# R7FA6M3AH register map
Vendor: Renesas; Series: RA6; File version: 1.2
CPU: CM4 r0p1, little endian, MPU, FPU, VTOR, 4 interrupt priority bits
Registers are 32-bit, read-write, reset 0x0 unless marked. A register's access mark holds for its fields unless they carry their own. Offsets are from the block's base; [hi:lo] are bit positions; {n}, {i} and the like mark numbered series; 'fields as' and 'values as' point back to an identical list.

## EPTPC_CFG — EPTPC Configulation
Base 0x40064500
0x00 PTRSTR — EPTPC Reset Register
  [0] RESET — EPTPC Software Reset
    0=Do not reset the EPTPC; 1=Reset the EPTPC. Do not access the EPTPC-related registers other than this register while a software reset is being issued.
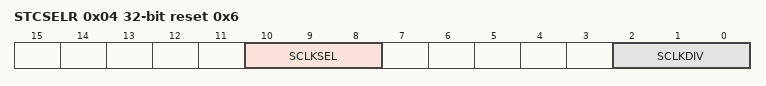
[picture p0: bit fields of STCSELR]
0x04 STCSELR reset 0x6 — STCA Clock Select Register
  [10:8] SCLKSEL — STCA Clock Select
    0=PCLKA clock divided by 1 to 6; 2=Input clock from the REF50CK0 pin; other=others (Settings other than above are prohibited.)
  [2:0] SCLKDIV — PCLKA Clock Frequency Division
    1=1; {v}=1/{v} (v=2..6); other=others (Settings other than above are prohibited.)
0x08 BYPASS — Bypass 1588 module Register
  [0] BYPASS0 — Bypass 1588 module for Ether 0ch
    0=to use 1588 module for Ether 0ch; 1=to bypass 1588 module for Ether 0ch

## CRC — CRC Calculator
Base 0x40074000
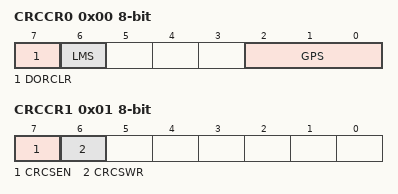
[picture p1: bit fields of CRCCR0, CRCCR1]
0x00 CRCCR0 8-bit — CRC Control Register0
  [7] DORCLR wo — CRCDOR Register Clear
    0=No effect; 1=Clears the CRCDOR register
  [6] LMS — CRC Calculation Switching
    0=Generates CRC for LSB first communication; 1=Generates CRC for MSB first communication
  [2:0] GPS — CRC Generating Polynomial Switching
    0=No calculation is executed; 1=8-bit CRC-8 (X8 + X2 + X + 1); 2=16-bit CRC-16 (X16 + X15 + X2 + 1); 3=16-bit CRC-CCITT (X16 + X12 + X5 + 1); 4=32-bit CRC-32 (X32+X26+X23+X22+X16+X12+X11+X10+X8+X7+X5+X4+X2+X+1); 5=32-bit CRC-32C (X32+X28+X27+X26+ X25+X23+X22+X20+X19+X18+X14+X13+X11+X10+X9+X8+X6+1); other=others (No calculation is executed.)
0x01 CRCCR1 8-bit — CRC Control Register1
  [7] CRCSEN — Snoop enable bit
    0=Disabled; 1=Enabled
  [6] CRCSWR — Snoop-on-write/read switch bit
    0=Snoop-on-read; 1=Snoop-on-write
0x04 CRCDIR — CRC Data Input Register
  [31:0] CRCDIR — Calculation input Data (Case of CRC-32, CRC-32C )
0x04 CRCDIR_BY 8-bit (alternate view of CRCDIR) — CRC Data Input Register (byte access)
  [7:0] CRCDIR_BY — Calculation input Data ( Case of CRC-8, CRC-16 or CRC-CCITT )
0x08 CRCDOR — CRC Data Output Register
  [31:0] CRCDOR — Calculation output Data (Case of CRC-32, CRC-32C )
0x08 CRCDOR_HA 16-bit (alternate view of CRCDOR) — CRC Data Output Register (halfword access)
  [15:0] CRCDOR_HA — Calculation output Data (Case of CRC-16 or CRC-CCITT )
0x08 CRCDOR_BY 8-bit (alternate view of CRCDOR) — CRC Data Output Register(byte access)
  [7:0] CRCDOR_BY — Calculation output Data (Case of CRC-8 )
0x0C CRCSAR 16-bit — Snoop Address Register
  [13:0] CRCSA — snoop address bitSet the I/O register address to snoop
    3=SCI0.TDR; 5=SCI0.RDR; 35=SCI1.TDR; 37=SCI1.RDR; 67=SCI2.TDR; 69=SCI2.RDR; 99=SCI3.TDR; 101=SCI3.RDR; 131=SCI4.TDR; 133=SCI4.RDR; 163=SCI5.TDR; 165=SCI5.RDR; 195=SCI6.TDR; 197=SCI6.RDR; 227=SCI7.TDR; 229=SCI7.RDR; 0x103=SCI8.TDR; 0x105=SCI8.RDR; 0x123=SCI9.TDR; 0x125=SCI9.RDR; other=others (Settings other than above are prohibited.)

## SPMON — CPU Stack Pointer Monitor
Base 0x40000D00
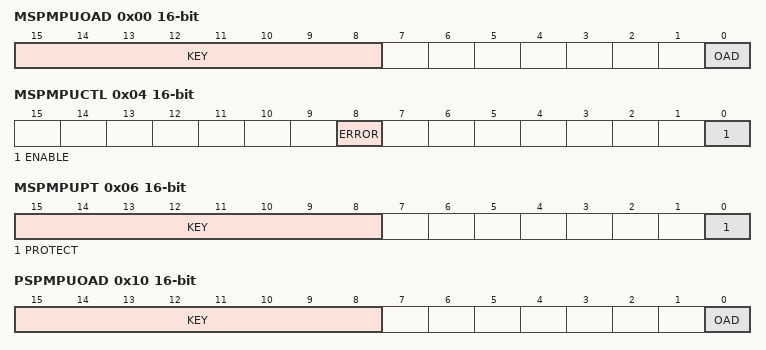
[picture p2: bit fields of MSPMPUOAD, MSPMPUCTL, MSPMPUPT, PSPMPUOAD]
0x00 MSPMPUOAD 16-bit — Stack Pointer Monitor Operation After Detection Register
  [15:8] KEY wo — Write Keyword The data written to these bits are not stored.
    165=Writing to the OAD bit is valid, when the KEY bits are written 0xA5; other=others (Writing to the OAD bit is invalid.)
  [0] OAD — Operation after detection
    1=Internal reset; 0=Non-maskable interrupt
0x04 MSPMPUCTL 16-bit — Stack Pointer Monitor Access Control Register
  [8] ERROR ro — SP_main monitor error flag
    0=SP_main has not overflowed or underflowed; 1=SP_main has overflowed or underflowed
  [0] ENABLE — SP_main monitor enable
    0=SP_main monitor is disabled; 1=SP_main monitor is enabled
0x06 MSPMPUPT 16-bit — Stack Pointer Monitor Protection Register
  [15:8] KEY wo — Write Keyword The data written to these bits are not stored.
    165=Writing to the PROTECT bit is valid, when the KEY bits are written 0xA5; other=others (Writing to the PROTECT bit is invalid.)
  [0] PROTECT — Protection of register (MSPMPUAC, MSPMPUSA and MSPMPUSE)
    0=Stack Pointer Monitor register writing is possible; 1=Stack Pointer Monitor register writing is protected
0x08 MSPMPUSA (reset mask 0x3) — Main Stack Pointer Monitor Start Address Register
  [31:2] MSPMPUSA range 0x1FF00000..0x200FFFFC — Region start address register Address where the region starts, for use in region determination.NOTE: Range: 0x1FF00000-0x200FFFFC The low-order 2 bits are fixed to 0.
0x0C MSPMPUEA reset 0x3 (reset mask 0x3) — Main Stack Pointer Monitor End Address Register
  [31:2] MSPMPUEA range 0x1FF00003..0x200FFFFF — Region end address register Address where the region starts, for use in region determination.NOTE: Range: 0x1FF00003-0x200FFFFF The low-order 2 bits are fixed to 1.
0x10 PSPMPUOAD 16-bit — Stack Pointer Monitor Operation After Detection Register
  fields as MSPMPUOAD
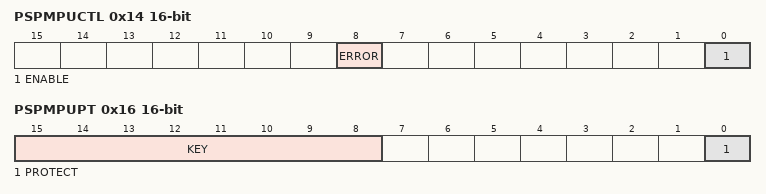
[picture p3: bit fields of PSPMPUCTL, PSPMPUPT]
0x14 PSPMPUCTL 16-bit (reset mask 0xFEFF) — Stack Pointer Monitor Access Control Register
  [8] ERROR ro — SP_process monitor error flag
    0=SP_process has not overflowed or underflowed; 1=SP_process has overflowed or underflowed
  [0] ENABLE — SP_process monitor enable
    0=SP_process monitor is disabled; 1=SP_process monitor is enabled
0x16 PSPMPUPT 16-bit — Stack Pointer Monitor Protection Register
  [15:8] KEY wo — Write Keyword The data written to these bits are not stored.
    values as MSPMPUPT.KEY
  [0] PROTECT — Protection of register (PSPMPUAC, PSPMPUSA and PSPMPUSE)
    values as MSPMPUPT.PROTECT
0x18 PSPMPUSA (reset mask 0x3) — Process Stack Pointer Monitor Start Address Register
  [31:2] PSPMPUSA range 0x1FF00000..0x200FFFFC — Region start address register Address where the region starts, for use in region determination.NOTE: Range: 0x1FF00000-0x200FFFFC The low-order 2 bits are fixed to 0.
0x1C PSPMPUEA reset 0x3 (reset mask 0x3) — Process Stack Pointer Monitor End Address Register
  [31:2] PSPMPUEA range 0x1FF00003..0x200FFFFF — Region end address register Address where the region starts, for use in region determination.NOTE: Range: 0x1FF00003-0x200FFFFF The low-order 2 bits are fixed to 1.
